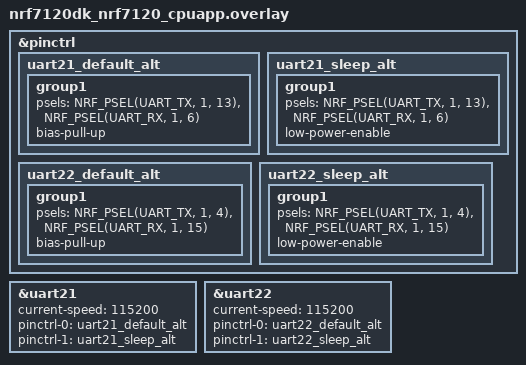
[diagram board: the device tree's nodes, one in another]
/* Required loopbacks:
 * P1.04 <-> P1.06
 * P1.13 <-> P1.15
 */

&pinctrl {
	uart21_default_alt: uart21_default_alt {
		group1 {
			psels = <NRF_PSEL(UART_TX, 1, 13)>,
				<NRF_PSEL(UART_RX, 1, 6)>;
			bias-pull-up;
		};
	};

	uart21_sleep_alt: uart21_sleep_alt {
		group1 {
			psels = <NRF_PSEL(UART_TX, 1, 13)>,
				<NRF_PSEL(UART_RX, 1, 6)>;
			low-power-enable;
		};
	};

	uart22_default_alt: uart22_default_alt {
		group1 {
			psels = <NRF_PSEL(UART_TX, 1, 4)>,
				<NRF_PSEL(UART_RX, 1, 15)>;
			bias-pull-up;
		};
	};

	uart22_sleep_alt: uart22_sleep_alt {
		group1 {
			psels = <NRF_PSEL(UART_TX, 1, 4)>,
				<NRF_PSEL(UART_RX, 1, 15)>;
			low-power-enable;
		};
	};
};

dut_uart_a: &uart21 {
	status = "okay";
	current-speed = <115200>;
	pinctrl-0 = <&uart21_default_alt>;
	pinctrl-1 = <&uart21_sleep_alt>;
	pinctrl-names = "default", "sleep";
};

dut_uart_b: &uart22 {
	status = "okay";
	current-speed = <115200>;
	pinctrl-0 = <&uart22_default_alt>;
	pinctrl-1 = <&uart22_sleep_alt>;
	pinctrl-names = "default", "sleep";
};
